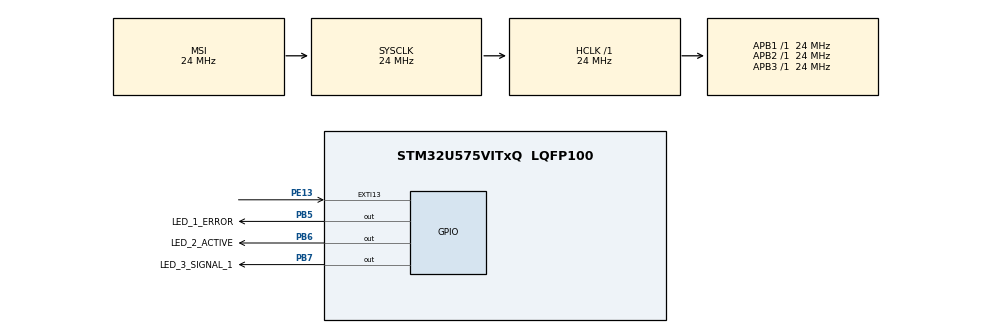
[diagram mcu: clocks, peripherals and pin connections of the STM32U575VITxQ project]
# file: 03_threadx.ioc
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CORTEX_M33_NS.userName=CORTEX_M33
Mcu.Family=STM32U5
Mcu.Name=STM32U575VITxQ
Mcu.Package=LQFP100
NVIC.EXTI13_IRQn=true\:0\:0\:false\:false\:true\:false\:true\:true\:true
NVIC.PriorityGroup=NVIC_PRIORITYGROUP_4
NVIC.TIM6_IRQn=true\:0\:0\:false\:false\:true\:false\:false\:true\:true
NVIC.TimeBase=TIM6_IRQn
NVIC.TimeBaseIP=TIM6
PA13\ (JTMS/SWDIO).Mode=Trace_Asynchronous_SW
PA13\ (JTMS/SWDIO).Signal=DEBUG_JTMS-SWDIO
PA14\ (JTCK/SWCLK).Mode=Trace_Asynchronous_SW
PA14\ (JTCK/SWCLK).Signal=DEBUG_JTCK-SWCLK
PB3\ (JTDO/TRACESWO).Mode=Trace_Asynchronous_SW
PB3\ (JTDO/TRACESWO).Signal=DEBUG_JTDO-SWO
PB5.GPIO_Label=LED_1_ERROR
PB5.Signal=GPIO_Output
PB6.GPIO_Label=LED_2_ACTIVE
PB6.Signal=GPIO_Output
PB7.GPIO_Label=LED_3_SIGNAL_1
PB7.Signal=GPIO_Output
PC14-OSC32_IN\ (PC14).Mode=LSE-External-Oscillator
PC14-OSC32_IN\ (PC14).Signal=RCC_OSC32_IN
PC15-OSC32_OUT\ (PC15).Mode=LSE-External-Oscillator
PC15-OSC32_OUT\ (PC15).Signal=RCC_OSC32_OUT
PE13.Signal=GPXTI13
PWR.PowerMode=PWR_SMPS_SUPPLY
ProjectManager.HeapSize=0x200
ProjectManager.StackSize=0x400
ProjectManager.TargetToolchain=STM32CubeIDE
RCC.ADCFreq_Value=16000000
RCC.AHBFreq_Value=24000000
RCC.APB1Freq_Value=24000000
RCC.APB1TimFreq_Value=24000000
RCC.APB2Freq_Value=24000000
RCC.APB2TimFreq_Value=24000000
RCC.APB3Freq_Value=24000000
RCC.CortexFreq_Value=24000000
RCC.EPOD_VALUE=24000000
RCC.HCLKFreq_Value=24000000
RCC.HSE_VALUE=16000000
RCC.HSI48_VALUE=48000000
RCC.HSI_VALUE=16000000
RCC.LSIDIV_VALUE=32000
RCC.MSIClockRange=RCC_MSIRANGE_1
RCC.MSIKClockRange=RCC_MSIKRANGE_7
RCC.MSI_VALUE=24000000
RCC.SYSCLKFreq_VALUE=24000000
RCC.USBFreq_Value=48000000
RCC.VCOOutputFreq_Value=3096000000
RTC.WakeUpClock-WakeUp=RTC_WAKEUPCLOCK_CK_SPRE_16BITS
RTC.WakeUpCounter-WakeUp=1
THREADX.TX_APP_CREATION=1
THREADX.TX_APP_GENERATE_INIT_CODE=true
THREADX.TX_APP_MEM_POOL_SIZE=3*1024
THREADX.TX_APP_SEM_CREATION=1
THREADX.TX_LOW_POWER=1
VP_ICACHE_VS_ICACHE.Mode=DirectMappedCache
VP_LPBAMQUEUE_VS_QUEUE.Mode=QUEUEMODE
VP_LPBAM_VS_SIG1.Mode=SmartRun
VP_LPBAM_VS_SIG4.Mode=LPDMA1
VP_MEMORYMAP_VS_MEMORYMAP.Mode=CurAppReg
VP_PWR_VS_DBSignals.Mode=DisableDeadBatterySignals
VP_PWR_VS_LPOM.Mode=PowerOptimisation
VP_PWR_VS_SECSignals.Mode=Security/Privilege
VP_RTC_VS_RTC_Activate.Mode=RTC_Enabled
VP_RTC_VS_RTC_WakeUp_intern.Mode=WakeUp
VP_SYS_VS_tim6.Mode=TIM6
VP_THREADX_VS_RTOSJjThreadXJjCoreJjDefault.Mode=Core_Default
VP_THREADX_VS_RTOSJjThreadXJjLow_Power_Support.Mode=Low_Power_Support
board=custom

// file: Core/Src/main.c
/* USER CODE BEGIN Header */
/**
  ******************************************************************************
  * @file           : main.c
  * @brief          : Main program body
  ******************************************************************************
  * @attention
  *
  * Copyright (c) 2023 STMicroelectronics.
  * All rights reserved.
  *
  * This software is licensed under terms that can be found in the LICENSE file
  * in the root directory of this software component.
  * If no LICENSE file comes with this software, it is provided AS-IS.
  *
  ******************************************************************************
  */
/* USER CODE END Header */
#include "app_threadx.h"
#include "main.h"

/* USER CODE BEGIN PD */

#define WAIT_FOR_STLINK 1000 // Retardo luego de programar.

/* USER CODE END PD */

RTC_HandleTypeDef hrtc;

void SystemClock_Config(void);
static void SystemPower_Config(void);
static void MX_ICACHE_Init(void);
static void MX_RTC_Init(void);

int main(void)
{

  /* MCU Configuration--------------------------------------------------------*/

  /* Reset of all peripherals, Initializes the Flash interface and the Systick. */
  HAL_Init();

  /* Configure the system clock */
  SystemClock_Config();

  /* Configure the System Power */
  SystemPower_Config();

  /* Initialize all configured peripherals */
  MX_GPIO_Init();
  MX_ICACHE_Init();
  MX_RTC_Init();
  /* USER CODE BEGIN 2 */

  // Se asegura un retardo antes de ingresar
  HAL_Delay(WAIT_FOR_STLINK);

  /* USER CODE END 2 */

  MX_ThreadX_Init();

  /* We should never get here as control is now taken by the scheduler */
  /* Infinite loop */
  while (1)
  {

  }
}

void SystemClock_Config(void)
{
  RCC_OscInitTypeDef RCC_OscInitStruct = {0};
  RCC_ClkInitTypeDef RCC_ClkInitStruct = {0};

  /** Configure the main internal regulator output voltage
  */
  if (HAL_PWREx_ControlVoltageScaling(PWR_REGULATOR_VOLTAGE_SCALE4) != HAL_OK)
  {
    Error_Handler();
  }

  /** Initializes the CPU, AHB and APB buses clocks
  */
  RCC_OscInitStruct.OscillatorType = RCC_OSCILLATORTYPE_LSI|RCC_OSCILLATORTYPE_MSI;
  RCC_OscInitStruct.LSIState = RCC_LSI_ON;
  RCC_OscInitStruct.MSIState = RCC_MSI_ON;
  RCC_OscInitStruct.MSICalibrationValue = RCC_MSICALIBRATION_DEFAULT;
  RCC_OscInitStruct.MSIClockRange = RCC_MSIRANGE_1;
  RCC_OscInitStruct.LSIDiv = RCC_LSI_DIV1;
  RCC_OscInitStruct.PLL.PLLState = RCC_PLL_NONE;
  if (HAL_RCC_OscConfig(&RCC_OscInitStruct) != HAL_OK)
  {
    Error_Handler();
  }

  /** Initializes the CPU, AHB and APB buses clocks
  */
  RCC_ClkInitStruct.ClockType = RCC_CLOCKTYPE_HCLK|RCC_CLOCKTYPE_SYSCLK
                              |RCC_CLOCKTYPE_PCLK1|RCC_CLOCKTYPE_PCLK2
                              |RCC_CLOCKTYPE_PCLK3;
  RCC_ClkInitStruct.SYSCLKSource = RCC_SYSCLKSOURCE_MSI;
  RCC_ClkInitStruct.AHBCLKDivider = RCC_SYSCLK_DIV1;
  RCC_ClkInitStruct.APB1CLKDivider = RCC_HCLK_DIV1;
  RCC_ClkInitStruct.APB2CLKDivider = RCC_HCLK_DIV1;
  RCC_ClkInitStruct.APB3CLKDivider = RCC_HCLK_DIV1;

  if (HAL_RCC_ClockConfig(&RCC_ClkInitStruct, FLASH_LATENCY_1) != HAL_OK)
  {
    Error_Handler();
  }
}

/**
  * @brief Power Configuration
  * @retval None
  */
static void SystemPower_Config(void)
{

  /*
   * Disable the internal Pull-Up in Dead Battery pins of UCPD peripheral
   */
  HAL_PWREx_DisableUCPDDeadBattery();

  /*
   * Switch to SMPS regulator instead of LDO
   */
  if (HAL_PWREx_ConfigSupply(PWR_SMPS_SUPPLY) != HAL_OK)
  {
    Error_Handler();
  }
}

static void MX_ICACHE_Init(void)
{

  /** Enable instruction cache in 1-way (direct mapped cache)
  */
  if (HAL_ICACHE_ConfigAssociativityMode(ICACHE_1WAY) != HAL_OK)
  {
    Error_Handler();
  }
  if (HAL_ICACHE_Enable() != HAL_OK)
  {
    Error_Handler();
  }

}

static void MX_RTC_Init(void)
{

  RTC_PrivilegeStateTypeDef privilegeState = {0};

  /** Initialize RTC Only
  */
  hrtc.Instance = RTC;
  hrtc.Init.HourFormat = RTC_HOURFORMAT_24;
  hrtc.Init.AsynchPrediv = 127;
  hrtc.Init.SynchPrediv = 255;
  hrtc.Init.OutPut = RTC_OUTPUT_DISABLE;
  hrtc.Init.OutPutRemap = RTC_OUTPUT_REMAP_NONE;
  hrtc.Init.OutPutPolarity = RTC_OUTPUT_POLARITY_HIGH;
  hrtc.Init.OutPutType = RTC_OUTPUT_TYPE_OPENDRAIN;
  hrtc.Init.OutPutPullUp = RTC_OUTPUT_PULLUP_NONE;
  hrtc.Init.BinMode = RTC_BINARY_NONE;
  if (HAL_RTC_Init(&hrtc) != HAL_OK)
  {
    Error_Handler();
  }
  privilegeState.rtcPrivilegeFull = RTC_PRIVILEGE_FULL_NO;
  privilegeState.backupRegisterPrivZone = RTC_PRIVILEGE_BKUP_ZONE_NONE;
  privilegeState.backupRegisterStartZone2 = RTC_BKP_DR0;
  privilegeState.backupRegisterStartZone3 = RTC_BKP_DR0;
  if (HAL_RTCEx_PrivilegeModeSet(&hrtc, &privilegeState) != HAL_OK)
  {
    Error_Handler();
  }

  /** Enable the WakeUp
  */
  if (HAL_RTCEx_SetWakeUpTimer(&hrtc, 1, RTC_WAKEUPCLOCK_CK_SPRE_16BITS) != HAL_OK)
  {
    Error_Handler();
  }

}

void MX_GPIO_Init(void)
{
  GPIO_InitTypeDef GPIO_InitStruct = {0};

  /* GPIO Ports Clock Enable */
  __HAL_RCC_GPIOC_CLK_ENABLE();
  __HAL_RCC_GPIOE_CLK_ENABLE();
  __HAL_RCC_GPIOA_CLK_ENABLE();
  __HAL_RCC_GPIOB_CLK_ENABLE();

  /*Configure GPIO pin Output Level */
  HAL_GPIO_WritePin(GPIOB, LED_1_ERROR_Pin|LED_2_ACTIVE_Pin|LED_3_SIGNAL_1_Pin, GPIO_PIN_RESET);

  /*Configure GPIO pin : PE13 */
  GPIO_InitStruct.Pin = GPIO_PIN_13;
  GPIO_InitStruct.Mode = GPIO_MODE_IT_RISING;
  GPIO_InitStruct.Pull = GPIO_NOPULL;
  HAL_GPIO_Init(GPIOE, &GPIO_InitStruct);

  /*Configure GPIO pins : LED_1_ERROR_Pin LED_2_ACTIVE_Pin LED_3_SIGNAL_1_Pin */
  GPIO_InitStruct.Pin = LED_1_ERROR_Pin|LED_2_ACTIVE_Pin|LED_3_SIGNAL_1_Pin;
  GPIO_InitStruct.Mode = GPIO_MODE_OUTPUT_PP;
  GPIO_InitStruct.Pull = GPIO_NOPULL;
  GPIO_InitStruct.Speed = GPIO_SPEED_FREQ_LOW;
  HAL_GPIO_Init(GPIOB, &GPIO_InitStruct);

  /* EXTI interrupt init*/
  HAL_NVIC_SetPriority(EXTI13_IRQn, 0, 0);
  HAL_NVIC_EnableIRQ(EXTI13_IRQn);

}

/* USER CODE BEGIN 4 */
void App_Delay(uint32_t delay)
{
	uint32_t initial_time = tx_time_get();
	while((tx_time_get() - initial_time) < delay);
}

/* USER CODE END 4 */

void HAL_TIM_PeriodElapsedCallback(TIM_HandleTypeDef *htim)
{
  if (htim->Instance == TIM6) {
    HAL_IncTick();
  }
}

void Error_Handler(void)
{
  /* USER CODE BEGIN Error_Handler_Debug */
  /* User can add his own implementation to report the HAL error return state */
  __disable_irq();
  while (1)
  {
	  HAL_GPIO_WritePin(LED_1_ERROR_GPIO_Port, LED_1_ERROR_Pin, GPIO_PIN_SET);
	  HAL_Delay(500);
	  HAL_GPIO_WritePin(LED_1_ERROR_GPIO_Port, LED_1_ERROR_Pin, GPIO_PIN_RESET);
  }
  /* USER CODE END Error_Handler_Debug */
}
